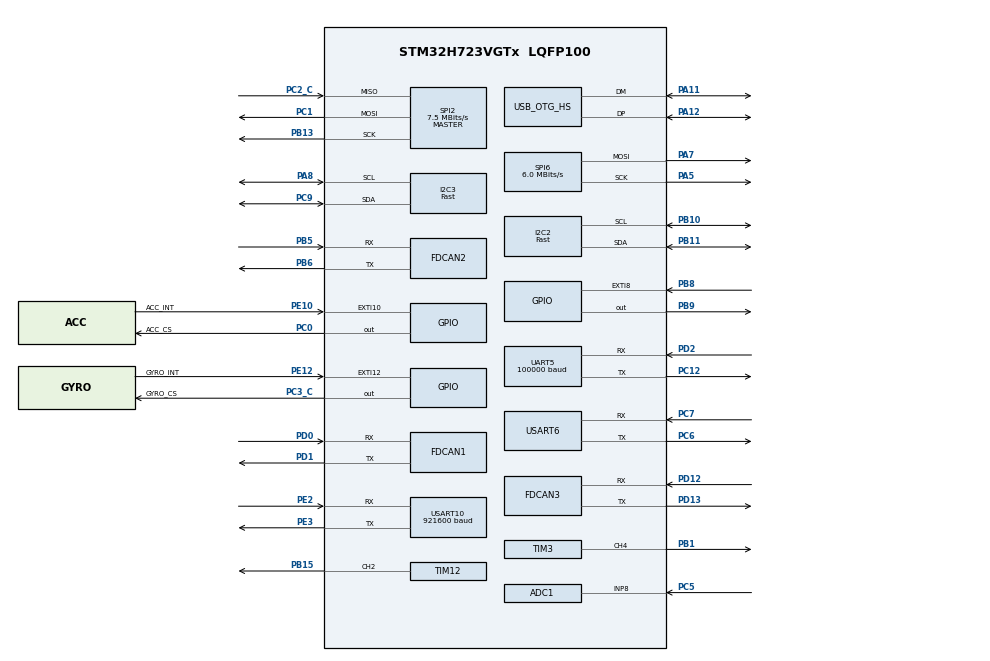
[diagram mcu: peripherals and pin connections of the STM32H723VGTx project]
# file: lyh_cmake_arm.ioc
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ADC1.Channel-0\#ChannelRegularConversion=ADC_CHANNEL_8
ADC1.ClockPrescaler=ADC_CLOCK_ASYNC_DIV4
ADC1.NbrOfConversionFlag=1
ADC1.OffsetNumber-0\#ChannelRegularConversion=ADC_OFFSET_NONE
ADC1.OffsetSignedSaturation-0\#ChannelRegularConversion=DISABLE
ADC1.Rank-0\#ChannelRegularConversion=1
ADC1.Resolution=ADC_RESOLUTION_12B
ADC1.SamplingTime-0\#ChannelRegularConversion=ADC_SAMPLETIME_1CYCLE_5
ADC1.master=1
ADC3.Channel-0\#ChannelRegularConversion=ADC_CHANNEL_TEMPSENSOR
ADC3.ClockPrescaler=ADC_CLOCK_ASYNC_DIV4
ADC3.NbrOfConversionFlag=1
ADC3.OffsetNumber-0\#ChannelRegularConversion=ADC_OFFSET_NONE
ADC3.OffsetSign-0\#ChannelRegularConversion=ADC3_OFFSET_SIGN_NEGATIVE
ADC3.Rank-0\#ChannelRegularConversion=1
ADC3.SamplingTime-0\#ChannelRegularConversion=ADC3_SAMPLETIME_2CYCLES_5
CORTEX_M7.default_mode_Activation=1
Dma.Request0=UART5_RX
Dma.Request1=SPI2_RX
Dma.Request2=SPI2_TX
Dma.Request3=USART6_RX
Dma.Request4=USART6_TX
Dma.Request5=USART10_RX
Dma.Request6=USART10_TX
Dma.SPI2_RX.1.Direction=DMA_PERIPH_TO_MEMORY
Dma.SPI2_RX.1.EventEnable=DISABLE
Dma.SPI2_RX.1.FIFOMode=DMA_FIFOMODE_DISABLE
Dma.SPI2_RX.1.Instance=DMA1_Stream0
Dma.SPI2_RX.1.MemDataAlignment=DMA_MDATAALIGN_BYTE
Dma.SPI2_RX.1.MemInc=DMA_MINC_ENABLE
Dma.SPI2_RX.1.Mode=DMA_NORMAL
Dma.SPI2_RX.1.PeriphDataAlignment=DMA_PDATAALIGN_BYTE
Dma.SPI2_RX.1.PeriphInc=DMA_PINC_DISABLE
Dma.SPI2_RX.1.Polarity=HAL_DMAMUX_REQ_GEN_RISING
Dma.SPI2_RX.1.Priority=DMA_PRIORITY_LOW
Dma.SPI2_RX.1.RequestNumber=1
Dma.SPI2_RX.1.SignalID=NONE
Dma.SPI2_RX.1.SyncEnable=DISABLE
Dma.SPI2_RX.1.SyncPolarity=HAL_DMAMUX_SYNC_NO_EVENT
Dma.SPI2_RX.1.SyncRequestNumber=1
Dma.SPI2_RX.1.SyncSignalID=NONE
Dma.SPI2_TX.2.Direction=DMA_MEMORY_TO_PERIPH
Dma.SPI2_TX.2.EventEnable=DISABLE
Dma.SPI2_TX.2.FIFOMode=DMA_FIFOMODE_DISABLE
Dma.SPI2_TX.2.Instance=DMA1_Stream1
Dma.SPI2_TX.2.MemDataAlignment=DMA_MDATAALIGN_BYTE
Dma.SPI2_TX.2.MemInc=DMA_MINC_ENABLE
Dma.SPI2_TX.2.Mode=DMA_NORMAL
Dma.SPI2_TX.2.PeriphDataAlignment=DMA_PDATAALIGN_BYTE
Dma.SPI2_TX.2.PeriphInc=DMA_PINC_DISABLE
Dma.SPI2_TX.2.Polarity=HAL_DMAMUX_REQ_GEN_RISING
Dma.SPI2_TX.2.Priority=DMA_PRIORITY_LOW
Dma.SPI2_TX.2.RequestNumber=1
Dma.SPI2_TX.2.SignalID=NONE
Dma.SPI2_TX.2.SyncEnable=DISABLE
Dma.SPI2_TX.2.SyncPolarity=HAL_DMAMUX_SYNC_NO_EVENT
Dma.SPI2_TX.2.SyncRequestNumber=1
Dma.SPI2_TX.2.SyncSignalID=NONE
Dma.UART5_RX.0.Direction=DMA_PERIPH_TO_MEMORY
Dma.UART5_RX.0.EventEnable=DISABLE
Dma.UART5_RX.0.FIFOMode=DMA_FIFOMODE_DISABLE
Dma.UART5_RX.0.Instance=DMA1_Stream2
Dma.UART5_RX.0.MemDataAlignment=DMA_MDATAALIGN_BYTE
Dma.UART5_RX.0.MemInc=DMA_MINC_ENABLE
Dma.UART5_RX.0.Mode=DMA_CIRCULAR
Dma.UART5_RX.0.PeriphDataAlignment=DMA_PDATAALIGN_BYTE
Dma.UART5_RX.0.PeriphInc=DMA_PINC_DISABLE
Dma.UART5_RX.0.Polarity=HAL_DMAMUX_REQ_GEN_RISING
Dma.UART5_RX.0.Priority=DMA_PRIORITY_VERY_HIGH
Dma.UART5_RX.0.RequestNumber=1
Dma.UART5_RX.0.SignalID=NONE
Dma.UART5_RX.0.SyncEnable=DISABLE
Dma.UART5_RX.0.SyncPolarity=HAL_DMAMUX_SYNC_NO_EVENT
Dma.UART5_RX.0.SyncRequestNumber=1
Dma.UART5_RX.0.SyncSignalID=NONE
Dma.USART10_RX.5.Direction=DMA_PERIPH_TO_MEMORY
Dma.USART10_RX.5.EventEnable=DISABLE
Dma.USART10_RX.5.FIFOMode=DMA_FIFOMODE_DISABLE
Dma.USART10_RX.5.Instance=DMA1_Stream5
Dma.USART10_RX.5.MemDataAlignment=DMA_MDATAALIGN_BYTE
Dma.USART10_RX.5.MemInc=DMA_MINC_ENABLE
Dma.USART10_RX.5.Mode=DMA_NORMAL
Dma.USART10_RX.5.PeriphDataAlignment=DMA_PDATAALIGN_BYTE
Dma.USART10_RX.5.PeriphInc=DMA_PINC_DISABLE
Dma.USART10_RX.5.Polarity=HAL_DMAMUX_REQ_GEN_RISING
Dma.USART10_RX.5.Priority=DMA_PRIORITY_LOW
Dma.USART10_RX.5.RequestNumber=1
Dma.USART10_RX.5.SignalID=NONE
Dma.USART10_RX.5.SyncEnable=DISABLE
Dma.USART10_RX.5.SyncPolarity=HAL_DMAMUX_SYNC_NO_EVENT
Dma.USART10_RX.5.SyncRequestNumber=1
Dma.USART10_RX.5.SyncSignalID=NONE
Dma.USART10_TX.6.Direction=DMA_MEMORY_TO_PERIPH
Dma.USART10_TX.6.EventEnable=DISABLE
Dma.USART10_TX.6.FIFOMode=DMA_FIFOMODE_DISABLE
Dma.USART10_TX.6.Instance=DMA1_Stream6
Dma.USART10_TX.6.MemDataAlignment=DMA_MDATAALIGN_BYTE
Dma.USART10_TX.6.MemInc=DMA_MINC_ENABLE
Dma.USART10_TX.6.Mode=DMA_NORMAL
Dma.USART10_TX.6.PeriphDataAlignment=DMA_PDATAALIGN_BYTE
Dma.USART10_TX.6.PeriphInc=DMA_PINC_DISABLE
Dma.USART10_TX.6.Polarity=HAL_DMAMUX_REQ_GEN_RISING
Dma.USART10_TX.6.Priority=DMA_PRIORITY_LOW
Dma.USART10_TX.6.RequestNumber=1
Dma.USART10_TX.6.SignalID=NONE
Dma.USART10_TX.6.SyncEnable=DISABLE
Dma.USART10_TX.6.SyncPolarity=HAL_DMAMUX_SYNC_NO_EVENT
Dma.USART10_TX.6.SyncRequestNumber=1
Dma.USART10_TX.6.SyncSignalID=NONE
Dma.USART6_RX.3.Direction=DMA_PERIPH_TO_MEMORY
Dma.USART6_RX.3.EventEnable=DISABLE
Dma.USART6_RX.3.FIFOMode=DMA_FIFOMODE_DISABLE
Dma.USART6_RX.3.Instance=DMA1_Stream3
Dma.USART6_RX.3.MemDataAlignment=DMA_MDATAALIGN_BYTE
Dma.USART6_RX.3.MemInc=DMA_MINC_ENABLE
Dma.USART6_RX.3.Mode=DMA_CIRCULAR
Dma.USART6_RX.3.PeriphDataAlignment=DMA_PDATAALIGN_BYTE
Dma.USART6_RX.3.PeriphInc=DMA_PINC_DISABLE
Dma.USART6_RX.3.Polarity=HAL_DMAMUX_REQ_GEN_RISING
Dma.USART6_RX.3.Priority=DMA_PRIORITY_LOW
Dma.USART6_RX.3.RequestNumber=1
Dma.USART6_RX.3.SignalID=NONE
Dma.USART6_RX.3.SyncEnable=DISABLE
Dma.USART6_RX.3.SyncPolarity=HAL_DMAMUX_SYNC_NO_EVENT
Dma.USART6_RX.3.SyncRequestNumber=1
Dma.USART6_RX.3.SyncSignalID=NONE
Dma.USART6_TX.4.Direction=DMA_MEMORY_TO_PERIPH
Dma.USART6_TX.4.EventEnable=DISABLE
Dma.USART6_TX.4.FIFOMode=DMA_FIFOMODE_DISABLE
Dma.USART6_TX.4.Instance=DMA1_Stream4
Dma.USART6_TX.4.MemDataAlignment=DMA_MDATAALIGN_BYTE
Dma.USART6_TX.4.MemInc=DMA_MINC_ENABLE
Dma.USART6_TX.4.Mode=DMA_NORMAL
Dma.USART6_TX.4.PeriphDataAlignment=DMA_PDATAALIGN_BYTE
Dma.USART6_TX.4.PeriphInc=DMA_PINC_DISABLE
Dma.USART6_TX.4.Polarity=HAL_DMAMUX_REQ_GEN_RISING
Dma.USART6_TX.4.Priority=DMA_PRIORITY_LOW
Dma.USART6_TX.4.RequestNumber=1
Dma.USART6_TX.4.SignalID=NONE
Dma.USART6_TX.4.SyncEnable=DISABLE
Dma.USART6_TX.4.SyncPolarity=HAL_DMAMUX_SYNC_NO_EVENT
Dma.USART6_TX.4.SyncRequestNumber=1
Dma.USART6_TX.4.SyncSignalID=NONE
FDCAN1.CalculateBaudRateNominal=1000000
FDCAN1.CalculateTimeBitNominal=1000
FDCAN1.CalculateTimeQuantumNominal=25.0
FDCAN1.DataPrescaler=3
FDCAN1.DataSyncJumpWidth=10
FDCAN1.DataTimeSeg1=29
FDCAN1.DataTimeSeg2=10
FDCAN1.NominalPrescaler=3
FDCAN1.NominalSyncJumpWidth=10
FDCAN1.NominalTimeSeg1=29
FDCAN1.NominalTimeSeg2=10
FDCAN1.ProtocolException=ENABLE
FDCAN1.RxFifo0ElmtsNbr=4
FDCAN1.StdFiltersNbr=1
FDCAN1.TxFifoQueueElmtsNbr=4
FDCAN2.CalculateBaudRateNominal=1000000
FDCAN2.CalculateTimeBitNominal=1000
FDCAN2.CalculateTimeQuantumNominal=25.0
FDCAN2.DataPrescaler=3
FDCAN2.DataSyncJumpWidth=10
FDCAN2.DataTimeSeg1=29
FDCAN2.DataTimeSeg2=10
FDCAN2.MessageRAMOffset=853
FDCAN2.NominalPrescaler=3
FDCAN2.NominalSyncJumpWidth=10
FDCAN2.NominalTimeSeg1=29
FDCAN2.NominalTimeSeg2=10
FDCAN2.ProtocolException=ENABLE
FDCAN2.RxFifo0ElmtsNbr=4
FDCAN2.StdFiltersNbr=1
FDCAN2.TxEventsNbr=0
FDCAN2.TxFifoQueueElmtsNbr=4
FDCAN3.CalculateBaudRateNominal=1000000
FDCAN3.CalculateTimeBitNominal=1000
FDCAN3.CalculateTimeQuantumNominal=25.0
FDCAN3.DataPrescaler=3
FDCAN3.DataSyncJumpWidth=10
FDCAN3.DataTimeSeg1=29
FDCAN3.DataTimeSeg2=10
FDCAN3.MessageRAMOffset=1706
FDCAN3.NominalPrescaler=3
FDCAN3.NominalSyncJumpWidth=10
FDCAN3.NominalTimeSeg1=29
FDCAN3.NominalTimeSeg2=10
FDCAN3.ProtocolException=ENABLE
FDCAN3.RxFifo0ElmtsNbr=4
FDCAN3.StdFiltersNbr=1
FDCAN3.TxFifoQueueElmtsNbr=4
FREERTOS.Tasks01=defaultTask,24,128,StartDefaultTask,Default,NULL,Dynamic,NULL,NULL;robotTask,40,512,StartRobotTask,Default,NULL,Dynamic,NULL,NULL
FREERTOS.configUSE_TICK_HOOK=1
I2C2.CustomTiming=Enabled
I2C2.I2C_Speed_Mode=I2C_Fast
I2C2.Timing=0x307075B1
I2C3.CustomTiming=Enabled
I2C3.I2C_Speed_Mode=I2C_Fast
I2C3.Timing=0x307075B1
Mcu.Family=STM32H7
Mcu.Name=STM32H723VGTx
Mcu.Package=LQFP100
NVIC.DMA1_Stream0_IRQn=true\:5\:0\:false\:false\:true\:true\:false\:true\:true
NVIC.DMA1_Stream1_IRQn=true\:5\:0\:false\:false\:true\:true\:false\:true\:true
NVIC.DMA1_Stream2_IRQn=true\:5\:0\:false\:false\:true\:true\:false\:true\:true
NVIC.DMA1_Stream3_IRQn=true\:5\:0\:false\:false\:true\:true\:false\:true\:true
NVIC.DMA1_Stream4_IRQn=true\:5\:0\:false\:false\:true\:true\:false\:true\:true
NVIC.DMA1_Stream5_IRQn=true\:5\:0\:false\:false\:true\:true\:false\:true\:true
NVIC.DMA1_Stream6_IRQn=true\:5\:0\:false\:false\:true\:true\:false\:true\:true
NVIC.EXTI15_10_IRQn=true\:5\:0\:false\:false\:true\:false\:true\:true\:true
NVIC.FDCAN1_IT0_IRQn=true\:5\:0\:false\:false\:true\:true\:true\:true\:true
NVIC.FDCAN2_IT0_IRQn=true\:5\:0\:false\:false\:true\:true\:true\:true\:true
NVIC.FDCAN3_IT0_IRQn=true\:5\:0\:false\:false\:true\:true\:true\:true\:true
NVIC.OTG_HS_IRQn=true\:5\:0\:false\:false\:true\:true\:false\:true\:true
NVIC.PriorityGroup=NVIC_PRIORITYGROUP_4
NVIC.SPI2_IRQn=true\:5\:0\:false\:false\:true\:true\:false\:true\:true
NVIC.TIM2_IRQn=true\:15\:0\:false\:false\:true\:false\:false\:true\:true
NVIC.TimeBase=TIM2_IRQn
NVIC.TimeBaseIP=TIM2
NVIC.UART5_IRQn=true\:5\:0\:false\:false\:true\:true\:true\:true\:true
NVIC.USART10_IRQn=true\:5\:0\:false\:false\:true\:true\:true\:true\:true
NVIC.USART6_IRQn=true\:5\:0\:false\:false\:true\:true\:true\:true\:true
PA11.Mode=Device_Only_FS
PA11.Signal=USB_OTG_HS_DM
PA12.Mode=Device_Only_FS
PA12.Signal=USB_OTG_HS_DP
PA13(JTMS/SWDIO).Mode=Serial_Wire
PA13(JTMS/SWDIO).Signal=DEBUG_JTMS-SWDIO
PA14(JTCK/SWCLK).Mode=Serial_Wire
PA14(JTCK/SWCLK).Signal=DEBUG_JTCK-SWCLK
PA5.Mode=TX_Only_Simplex_Unidirect_Master
PA5.Signal=SPI6_SCK
PA7.Mode=TX_Only_Simplex_Unidirect_Master
PA7.Signal=SPI6_MOSI
PA8.Mode=I2C
PA8.Signal=I2C3_SCL
PB1.Signal=S_TIM3_CH4
PB10.Mode=I2C
PB10.Signal=I2C2_SCL
PB11.Mode=I2C
PB11.Signal=I2C2_SDA
PB13.GPIO_Speed=GPIO_SPEED_FREQ_VERY_HIGH
PB13.Mode=Full_Duplex_Master
PB13.Signal=SPI2_SCK
PB15.Signal=S_TIM12_CH2
PB5.Mode=FDCAN_Activate
PB5.Signal=FDCAN2_RX
PB6.Mode=FDCAN_Activate
PB6.Signal=FDCAN2_TX
PB8.Signal=GPXTI8
PB9.Signal=GPIO_Output
PC0.GPIO_Label=ACC_CS
PC0.GPIO_Speed=GPIO_SPEED_FREQ_VERY_HIGH
PC0.PinState=GPIO_PIN_SET
PC0.Signal=GPIO_Output
PC1.GPIO_Speed=GPIO_SPEED_FREQ_VERY_HIGH
PC1.Mode=Full_Duplex_Master
PC1.Signal=SPI2_MOSI
PC12.Mode=Asynchronous
PC12.Signal=UART5_TX
PC2_C.GPIO_Speed=GPIO_SPEED_FREQ_VERY_HIGH
PC2_C.Mode=Full_Duplex_Master
PC2_C.Signal=SPI2_MISO
PC3_C.GPIO_Label=GYRO_CS
PC3_C.GPIO_Speed=GPIO_SPEED_FREQ_VERY_HIGH
PC3_C.PinState=GPIO_PIN_SET
PC3_C.Signal=GPIO_Output
PC5.Signal=ADCx_INP8
PC6.GPIO_Speed=GPIO_SPEED_FREQ_VERY_HIGH
PC6.Mode=Asynchronous
PC6.Signal=USART6_TX
PC7.GPIO_Speed=GPIO_SPEED_FREQ_VERY_HIGH
PC7.Mode=Asynchronous
PC7.Signal=USART6_RX
PC9.Mode=I2C
PC9.Signal=I2C3_SDA
PD0.Mode=FDCAN_Activate
PD0.Signal=FDCAN1_RX
PD1.Mode=FDCAN_Activate
PD1.Signal=FDCAN1_TX
PD12.Mode=FDCAN_Activate
PD12.Signal=FDCAN3_RX
PD13.Mode=FDCAN_Activate
PD13.Signal=FDCAN3_TX
PD2.GPIO_Speed=GPIO_SPEED_FREQ_VERY_HIGH
PD2.Mode=Asynchronous
PD2.Signal=UART5_RX
PE10.GPIO_Label=ACC_INT
PE10.Signal=GPXTI10
PE12.GPIO_Label=GYRO_INT
PE12.Signal=GPXTI12
PE2.GPIO_Speed=GPIO_SPEED_FREQ_VERY_HIGH
PE2.Mode=Asynchronous
PE2.Signal=USART10_RX
PE3.GPIO_Speed=GPIO_SPEED_FREQ_VERY_HIGH
PE3.Mode=Asynchronous
PE3.Signal=USART10_TX
PH0-OSC_IN.Mode=HSE-External-Oscillator
PH0-OSC_IN.Signal=RCC_OSC_IN
PH1-OSC_OUT.Mode=HSE-External-Oscillator
PH1-OSC_OUT.Signal=RCC_OSC_OUT
ProjectManager.HeapSize=0x200
ProjectManager.StackSize=0x400
ProjectManager.TargetToolchain=CMake
RCC.ADCCLockSelection=RCC_ADCCLKSOURCE_PLL3
RCC.ADCFreq_Value=120000000
RCC.APB1Freq_Value=120000000
RCC.APB2Freq_Value=120000000
RCC.APB3Freq_Value=120000000
RCC.APB4Freq_Value=120000000
RCC.CortexFreq_Value=480000000
RCC.D1PPRE=RCC_APB3_DIV2
RCC.D2PPRE1=RCC_APB1_DIV2
RCC.D2PPRE2=RCC_APB2_DIV2
RCC.D3PPRE=RCC_APB4_DIV2
RCC.DIVM1=2
RCC.DIVM2=2
RCC.DIVM3=2
RCC.DIVN1=40
RCC.DIVN2=40
RCC.DIVN3=20
RCC.DIVP1=1
RCC.DIVQ1=4
RCC.DIVQ3=5
RCC.HCLKFreq_Value=240000000
RCC.HPRE=RCC_HCLK_DIV2
RCC.HSE_VALUE=24000000
RCC.PLLSourceVirtual=RCC_PLLSOURCE_HSE
RCC.SPI123CLockSelection=RCC_SPI123CLKSOURCE_PLL2
RCC.SPI6CLockSelection=RCC_SPI6CLKSOURCE_HSE
RCC.SYSCLKFreq_VALUE=480000000
RCC.SYSCLKSource=RCC_SYSCLKSOURCE_PLLCLK
RCC.USBCLockSelection=RCC_USBCLKSOURCE_PLL3
RCC.USBFreq_Value=48000000
SH.ADCx_INP8.0=ADC1_INP8,IN8-Single-Ended
SH.S_TIM12_CH2.0=TIM12_CH2,PWM Generation2 CH2
SH.S_TIM3_CH4.0=TIM3_CH4,PWM Generation4 CH4
SPI2.BaudRatePrescaler=SPI_BAUDRATEPRESCALER_32
SPI2.CLKPhase=SPI_PHASE_2EDGE
SPI2.CLKPolarity=SPI_POLARITY_HIGH
SPI2.CalculateBaudRate=7.5 MBits/s
SPI2.DataSize=SPI_DATASIZE_8BIT
SPI2.Direction=SPI_DIRECTION_2LINES
SPI2.Mode=SPI_MODE_MASTER
SPI2.VirtualType=VM_MASTER
SPI6.BaudRatePrescaler=SPI_BAUDRATEPRESCALER_4
SPI6.CLKPhase=SPI_PHASE_2EDGE
SPI6.CalculateBaudRate=6.0 MBits/s
SPI6.DataSize=SPI_DATASIZE_8BIT
SPI6.Direction=SPI_DIRECTION_2LINES_TXONLY
SPI6.Mode=SPI_MODE_MASTER
SPI6.VirtualType=VM_MASTER
TIM12.Channel-PWM\ Generation2\ CH2=TIM_CHANNEL_2
TIM12.Period=600-1
TIM12.Prescaler=100-1
TIM12.Pulse-PWM\ Generation2\ CH2=300-1
TIM3.Channel-PWM\ Generation4\ CH4=TIM_CHANNEL_4
TIM3.Period=5000-1
TIM3.Prescaler=0
UART5.BaudRate=100000
UART5.Parity=PARITY_EVEN
UART5.StopBits=UART_STOPBITS_2
UART5.WordLength=WORDLENGTH_9B
USART10.BaudRate=921600
USART10.VirtualMode=VM_ASYNC
USART6.VirtualMode=VM_ASYNC
USB_DEVICE.CLASS_NAME_HS=CDC
USB_DEVICE.VirtualMode=Cdc
USB_DEVICE.VirtualModeHS=Cdc_HS
USB_OTG_HS.VirtualMode-Device_Only_FS=Device_Only_FS
VP_ADC3_TempSens_Input.Mode=IN-TempSens
VP_FREERTOS_VS_CMSIS_V2.Mode=CMSIS_V2
VP_MEMORYMAP_VS_MEMORYMAP.Mode=CurAppReg
VP_SYS_VS_tim2.Mode=TIM2
VP_USB_DEVICE_VS_USB_DEVICE_CDC_HS.Mode=CDC_HS
board=custom

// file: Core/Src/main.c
/* USER CODE BEGIN Header */
/**
  ******************************************************************************
  * @file           : main.c
  * @brief          : Main program body
  ******************************************************************************
  * @attention
  *
  * Copyright (c) 2026 STMicroelectronics.
  * All rights reserved.
  *
  * This software is licensed under terms that can be found in the LICENSE file
  * in the root directory of this software component.
  * If no LICENSE file comes with this software, it is provided AS-IS.
  *
  ******************************************************************************
  */
/* USER CODE END Header */
#include "main.h"
#include "cmsis_os.h"
#include "adc.h"
#include "dma.h"
#include "fdcan.h"
#include "i2c.h"
#include "spi.h"
#include "tim.h"
#include "usart.h"
#include "usb_device.h"
#include "gpio.h"

/* USER CODE BEGIN Includes */
#include "bsp_can.h"
#include "robot_application.h"

/* USER CODE END Includes */

void SystemClock_Config(void);
void PeriphCommonClock_Config(void);
static void MPU_Config(void);
void MX_FREERTOS_Init(void);

int main(void)
{

  /* MPU Configuration--------------------------------------------------------*/
  MPU_Config();

  /* MCU Configuration--------------------------------------------------------*/

  /* Reset of all peripherals, Initializes the Flash interface and the Systick. */
  HAL_Init();

  /* Configure the system clock */
  SystemClock_Config();

  /* Configure the peripherals common clocks */
  PeriphCommonClock_Config();

  /* Initialize all configured peripherals */
  MX_GPIO_Init();
  MX_DMA_Init();
  MX_FDCAN1_Init();
  MX_FDCAN2_Init();
  MX_FDCAN3_Init();
  MX_TIM3_Init();
  MX_UART5_Init();
  MX_SPI2_Init();
  MX_SPI6_Init();
  MX_TIM12_Init();
  MX_USART6_UART_Init();
  MX_USART10_UART_Init();
  MX_ADC1_Init();
  MX_ADC3_Init();
  MX_I2C2_Init();
  MX_I2C3_Init();
  /* USER CODE BEGIN 2 */
  robot_application_init();
  if (!can_filter_init())
  {
    Error_Handler();
  }

  /* USER CODE END 2 */

  /* Init scheduler */
  osKernelInitialize();  /* Call init function for freertos objects (in cmsis_os2.c) */
  MX_FREERTOS_Init();

  /* Start scheduler */
  osKernelStart();

  /* We should never get here as control is now taken by the scheduler */

  /* Infinite loop */
  while (1)
  {

  }
}

void SystemClock_Config(void)
{
  RCC_OscInitTypeDef RCC_OscInitStruct = {0};
  RCC_ClkInitTypeDef RCC_ClkInitStruct = {0};

  /** Supply configuration update enable
  */
  HAL_PWREx_ConfigSupply(PWR_LDO_SUPPLY);

  /** Configure the main internal regulator output voltage
  */
  __HAL_PWR_VOLTAGESCALING_CONFIG(PWR_REGULATOR_VOLTAGE_SCALE0);

  while(!__HAL_PWR_GET_FLAG(PWR_FLAG_VOSRDY)) {}

  /** Initializes the RCC Oscillators according to the specified parameters
  * in the RCC_OscInitTypeDef structure.
  */
  RCC_OscInitStruct.OscillatorType = RCC_OSCILLATORTYPE_HSE;
  RCC_OscInitStruct.HSEState = RCC_HSE_ON;
  RCC_OscInitStruct.PLL.PLLState = RCC_PLL_ON;
  RCC_OscInitStruct.PLL.PLLSource = RCC_PLLSOURCE_HSE;
  RCC_OscInitStruct.PLL.PLLM = 2;
  RCC_OscInitStruct.PLL.PLLN = 40;
  RCC_OscInitStruct.PLL.PLLP = 1;
  RCC_OscInitStruct.PLL.PLLQ = 4;
  RCC_OscInitStruct.PLL.PLLR = 2;
  RCC_OscInitStruct.PLL.PLLRGE = RCC_PLL1VCIRANGE_3;
  RCC_OscInitStruct.PLL.PLLVCOSEL = RCC_PLL1VCOWIDE;
  RCC_OscInitStruct.PLL.PLLFRACN = 0;
  if (HAL_RCC_OscConfig(&RCC_OscInitStruct) != HAL_OK)
  {
    Error_Handler();
  }

  /** Initializes the CPU, AHB and APB buses clocks
  */
  RCC_ClkInitStruct.ClockType = RCC_CLOCKTYPE_HCLK|RCC_CLOCKTYPE_SYSCLK
                              |RCC_CLOCKTYPE_PCLK1|RCC_CLOCKTYPE_PCLK2
                              |RCC_CLOCKTYPE_D3PCLK1|RCC_CLOCKTYPE_D1PCLK1;
  RCC_ClkInitStruct.SYSCLKSource = RCC_SYSCLKSOURCE_PLLCLK;
  RCC_ClkInitStruct.SYSCLKDivider = RCC_SYSCLK_DIV1;
  RCC_ClkInitStruct.AHBCLKDivider = RCC_HCLK_DIV2;
  RCC_ClkInitStruct.APB3CLKDivider = RCC_APB3_DIV2;
  RCC_ClkInitStruct.APB1CLKDivider = RCC_APB1_DIV2;
  RCC_ClkInitStruct.APB2CLKDivider = RCC_APB2_DIV2;
  RCC_ClkInitStruct.APB4CLKDivider = RCC_APB4_DIV2;

  if (HAL_RCC_ClockConfig(&RCC_ClkInitStruct, FLASH_LATENCY_3) != HAL_OK)
  {
    Error_Handler();
  }
}

void PeriphCommonClock_Config(void)
{
  RCC_PeriphCLKInitTypeDef PeriphClkInitStruct = {0};

  /** Initializes the peripherals clock
  */
  PeriphClkInitStruct.PeriphClockSelection = RCC_PERIPHCLK_USB|RCC_PERIPHCLK_ADC;
  PeriphClkInitStruct.PLL3.PLL3M = 2;
  PeriphClkInitStruct.PLL3.PLL3N = 20;
  PeriphClkInitStruct.PLL3.PLL3P = 2;
  PeriphClkInitStruct.PLL3.PLL3Q = 5;
  PeriphClkInitStruct.PLL3.PLL3R = 2;
  PeriphClkInitStruct.PLL3.PLL3RGE = RCC_PLL3VCIRANGE_3;
  PeriphClkInitStruct.PLL3.PLL3VCOSEL = RCC_PLL3VCOWIDE;
  PeriphClkInitStruct.PLL3.PLL3FRACN = 0;
  PeriphClkInitStruct.UsbClockSelection = RCC_USBCLKSOURCE_PLL3;
  PeriphClkInitStruct.AdcClockSelection = RCC_ADCCLKSOURCE_PLL3;
  if (HAL_RCCEx_PeriphCLKConfig(&PeriphClkInitStruct) != HAL_OK)
  {
    Error_Handler();
  }
}

 /* MPU Configuration */

void MPU_Config(void)
{
  MPU_Region_InitTypeDef MPU_InitStruct = {0};

  /* Disables the MPU */
  HAL_MPU_Disable();

  /** Initializes and configures the Region and the memory to be protected
  */
  MPU_InitStruct.Enable = MPU_REGION_ENABLE;
  MPU_InitStruct.Number = MPU_REGION_NUMBER0;
  MPU_InitStruct.BaseAddress = 0x0;
  MPU_InitStruct.Size = MPU_REGION_SIZE_4GB;
  MPU_InitStruct.SubRegionDisable = 0x87;
  MPU_InitStruct.TypeExtField = MPU_TEX_LEVEL0;
  MPU_InitStruct.AccessPermission = MPU_REGION_NO_ACCESS;
  MPU_InitStruct.DisableExec = MPU_INSTRUCTION_ACCESS_DISABLE;
  MPU_InitStruct.IsShareable = MPU_ACCESS_SHAREABLE;
  MPU_InitStruct.IsCacheable = MPU_ACCESS_NOT_CACHEABLE;
  MPU_InitStruct.IsBufferable = MPU_ACCESS_NOT_BUFFERABLE;

  HAL_MPU_ConfigRegion(&MPU_InitStruct);
  /* Enables the MPU */
  HAL_MPU_Enable(MPU_PRIVILEGED_DEFAULT);

}

void HAL_TIM_PeriodElapsedCallback(TIM_HandleTypeDef *htim)
{
  if (htim->Instance == TIM2)
  {
    HAL_IncTick();
  }
}

void Error_Handler(void)
{
  __disable_irq();
  while (1)
  {
  }
}

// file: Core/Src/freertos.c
/* USER CODE BEGIN Header */
/**
  ******************************************************************************
  * File Name          : freertos.c
  * Description        : Code for freertos applications
  ******************************************************************************
  * @attention
  *
  * Copyright (c) 2026 STMicroelectronics.
  * All rights reserved.
  *
  * This software is licensed under terms that can be found in the LICENSE file
  * in the root directory of this software component.
  * If no LICENSE file comes with this software, it is provided AS-IS.
  *
  ******************************************************************************
  */
/* USER CODE END Header */

#include "FreeRTOS.h"
#include "task.h"
#include "main.h"
#include "cmsis_os.h"

/* USER CODE BEGIN Includes */
#include "robot_task.h"

/* USER CODE END Includes */

/* Definitions for defaultTask */
osThreadId_t defaultTaskHandle;
const osThreadAttr_t defaultTask_attributes = {
  .name = "defaultTask",
  .stack_size = 128 * 4,
  .priority = (osPriority_t) osPriorityNormal,
};
/* Definitions for robotTask */
osThreadId_t robotTaskHandle;
const osThreadAttr_t robotTask_attributes = {
  .name = "robotTask",
  .stack_size = 512 * 4,
  .priority = (osPriority_t) osPriorityHigh,
};

void StartDefaultTask(void *argument);
void StartRobotTask(void *argument);

extern void MX_USB_DEVICE_Init(void);
void MX_FREERTOS_Init(void); /* (MISRA C 2004 rule 8.1) */

/* Hook prototypes */
void vApplicationTickHook(void);

/* USER CODE BEGIN 3 */
void vApplicationTickHook( void )
{
   /* This function will be called by each tick interrupt if
   configUSE_TICK_HOOK is set to 1 in FreeRTOSConfig.h. User code can be
   added here, but the tick hook is called from an interrupt context, so
   code must not attempt to block, and only the interrupt safe FreeRTOS API
   functions can be used (those that end in FromISR()). */
}
/* USER CODE END 3 */

void MX_FREERTOS_Init(void) {

  /* Create the thread(s) */
  /* creation of defaultTask */
  defaultTaskHandle = osThreadNew(StartDefaultTask, NULL, &defaultTask_attributes);

  /* creation of robotTask */
  robotTaskHandle = osThreadNew(StartRobotTask, NULL, &robotTask_attributes);

}

void StartDefaultTask(void *argument)
{
  /* init code for USB_DEVICE */
  MX_USB_DEVICE_Init();
  for(;;)
  {
    osDelay(1);
  }
}

/* USER CODE BEGIN Header_StartRobotTask */
/* Fixed-period application task; motor protocol remains in model/motor. */
/* USER CODE END Header_StartRobotTask */
void StartRobotTask(void *argument)
{
  /* USER CODE BEGIN StartRobotTask */
  robot_task(argument);
  /* USER CODE END StartRobotTask */
}
